# STM32N647xx register map
File version: 1.0
Registers are 32-bit, read-write, reset 0x0 unless marked. A register's access mark holds for its fields unless they carry their own. Offsets are from the block's base; [hi:lo] are bit positions.

## SYSCFG — System configuration controller
Base 0x46008000
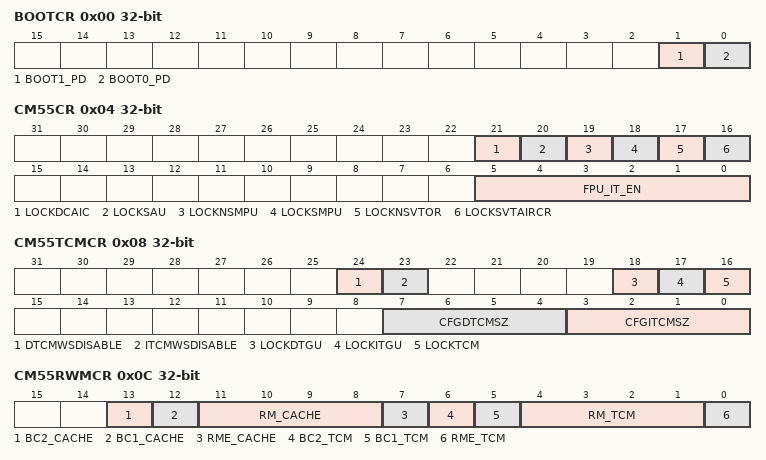
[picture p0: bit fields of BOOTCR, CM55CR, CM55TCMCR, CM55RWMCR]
0x00 BOOTCR — SYSCFG boot pin control register
  [1] BOOT1_PD — BOOT1 pin pull-down disable
  [0] BOOT0_PD — BOOT0 pin pull-down disable
0x04 CM55CR — SYSCFG Cortex-M55 control register
  [21] LOCKDCAIC
  [20] LOCKSAU — Prevent changes to secure SAU memory regions already programmed
  [19] LOCKNSMPU — Prevent changes to programmed non-secure MPU memory regions
  [18] LOCKSMPU — Prevent changes to programmed secure MPU memory regions
  [17] LOCKNSVTOR — Prevent changes to the non-secure vector table base address
  [16] LOCKSVTAIRCR
  [5:0] FPU_IT_EN — Enable FPU exception
0x08 CM55TCMCR — SYSCFG Cortex-M55 TCM control register
  [24] DTCMWSDISABLE — Disable wait-state applied by default on extended DTCM memory
  [23] ITCMWSDISABLE — Disable wait-state applied by default on extended ITCM memory
  [18] LOCKDTGU — Disable writes to registers associated with the DTCM interface security/gating
  [17] LOCKITGU — Disable writes to registers associated with the ITCM interface security/gating
  [16] LOCKTCM — Disable writes to registers associated with the TCM region
  [7:4] CFGDTCMSZ — Select DTCM memory size
  [3:0] CFGITCMSZ — Select ITCM memory size
0x0C CM55RWMCR — SYSCFG Cortex-M55 memory RW margin register
  [13] BC2_CACHE — Biasing level adjust input recommended for Vnom + 10%
  [12] BC1_CACHE — Biasing level adjust input recommended for Vnom
  [11:8] RM_CACHE — External read/write (RW) margin inputs for caches memories
  [7] RME_CACHE — RW margin enable input for caches memories
  [6] BC2_TCM — Biasing level adjust input recommended for Vnom + 10%
  [5] BC1_TCM — Biasing level adjust input recommended for Vnom
  [4:1] RM_TCM — External RW margin inputs for TCM memories
  [0] RME_TCM — RW margin enable input for TCM memories
0x10 INITSVTORCR — SYSCFG Cortex-M55 SVTOR control register
  [31:7] SVTOR_ADDR — Secure vector table base address
0x14 INITNSVTORCR — Cortex-M55 NSVTOR control register
  [31:7] NSVTOR_ADDR — Non-Secure vector table base address
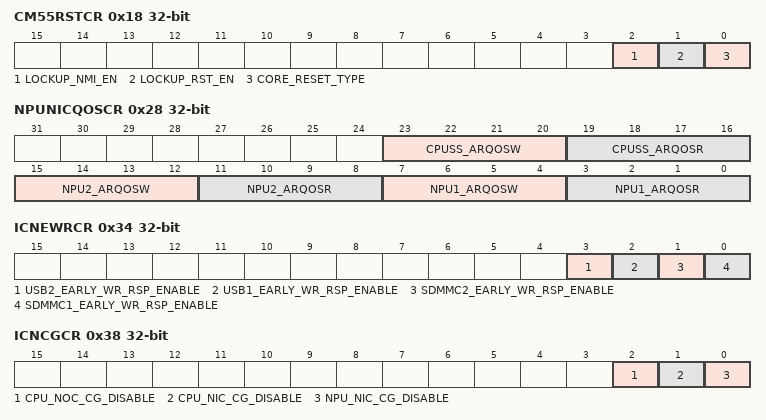
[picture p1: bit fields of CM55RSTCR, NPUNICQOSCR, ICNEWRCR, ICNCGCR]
0x18 CM55RSTCR — SYSCFG Cortex-M55 reset type control register
  [2] LOCKUP_NMI_EN — Select action to perform on a lockup state on the core
  [1] LOCKUP_RST_EN — Select action to perform on a lockup state on the core
  [0] CORE_RESET_TYPE — Select reset to apply on core upon SYSRESETREQ
0x1C CM55PAHBWPR — SYSCFG Cortex-M55 P-AHB write posting control register
  [0] PAHB_ERROR_ACK — Error capture in write posting buffer
0x20 VENCRAMCR — SYSCFG VENCRAM control register
  [0] VENCRAM_EN — VENCRAM allocation VENC if active, or to system (if VENC inactive)
0x24 POTTAMPRSTCR — SYSCFG potential tamper reset register
  [0] POTTAMPERSETMASK — mask PKA, SAES, CRYP1/2, and HASH reset, in case of potential tamper
0x28 NPUNICQOSCR — SYSCFG NPUNIC QoS control register
  [23:20] CPUSS_ARQOSW — NPUNIC write QoS information for master port from CPUSS
  [19:16] CPUSS_ARQOSR — NPUNIC read QoS information for master port from CPUSS
  [15:12] NPU2_ARQOSW — NPUNIC write QoS information for NPU2 master port
  [11:8] NPU2_ARQOSR — NPUNIC read QoS information for NPU2 master port
  [7:4] NPU1_ARQOSW — NPUNIC write QoS information for NPU1 master port
  [3:0] NPU1_ARQOSR — NPUNIC read QoS information for NPU1 master port
0x34 ICNEWRCR — SYSCFG AHB-AXI bridge early write response
  [3] USB2_EARLY_WR_RSP_ENABLE — USB2 early-write response
  [2] USB1_EARLY_WR_RSP_ENABLE — USB1 early-write response
  [1] SDMMC2_EARLY_WR_RSP_ENABLE — SDMMC2 early-write response
  [0] SDMMC1_EARLY_WR_RSP_ENABLE — SDMMC1 early-write response
0x38 ICNCGCR — SYSCFG ICN clock gating control register
  [2] CPU_NOC_CG_DISABLE — CPU_NOC clock gating disable
  [1] CPU_NIC_CG_DISABLE — CPU_NIC clock gating disable
  [0] NPU_NIC_CG_DISABLE — NPU_NIC clock gating disable
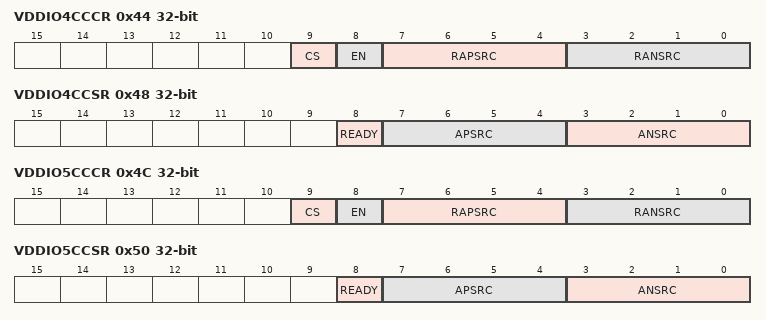
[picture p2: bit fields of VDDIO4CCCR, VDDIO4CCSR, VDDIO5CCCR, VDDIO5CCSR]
0x44 VDDIO4CCCR — SYSCFG VDDIO4 compensation cell control register
  [9] CS — Code selection for the compensation cell of I/Os supplied by VDDIO4
  [8] EN — Enables the compensation cell of I/Os supplied by VDDIO4
  [7:4] RAPSRC — I/O compensation code for PMOS transistors
  [3:0] RANSRC — I/O compensation code for NMOS transistors
0x48 VDDIO4CCSR — SYSCFG VDDIO4 compensation cell status register
  [8] READY — Provides the compensation cell status of I/Os supplied by VDDIO4
  [7:4] APSRC
  [3:0] ANSRC
0x4C VDDIO5CCCR — SYSCFG VDDIO5 compensation cell control register
  [9] CS — Code selection for the compensation cell of I/Os supplied by VDDIO5
  [8] EN — Enables the compensation cell of I/Os supplied by VDDIO5
  [7:4] RAPSRC — I/O compensation code for PMOS transistors
  [3:0] RANSRC — I/O compensation code for NMOS transistors
0x50 VDDIO5CCSR — SYSCFG VDDIO5 compensation cell status register
  [8] READY — Provides the compensation cell status of I/Os supplied by VDDIO5
  [7:4] APSRC
  [3:0] ANSRC
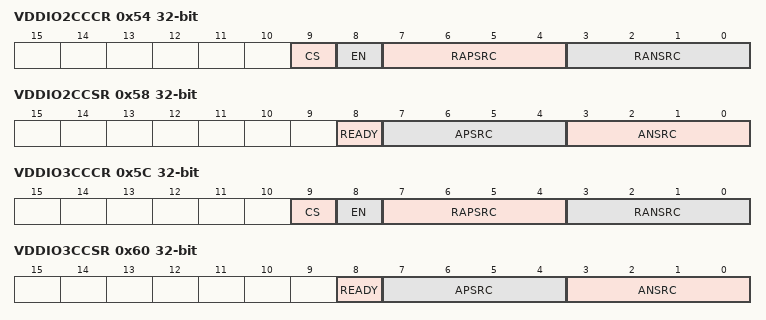
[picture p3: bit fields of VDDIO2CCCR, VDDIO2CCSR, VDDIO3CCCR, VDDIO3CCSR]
0x54 VDDIO2CCCR — SYSCFG VDDIO2 compensation cell control register
  [9] CS — Code selection for the compensation cell of I/Os supplied by VDDIO2
  [8] EN — Enables the compensation cell of I/Os supplied by VDDIO2
  [7:4] RAPSRC — I/O compensation code for PMOS transistors
  [3:0] RANSRC — I/O compensation code for NMOS transistors
0x58 VDDIO2CCSR — SYSCFG VDDIO2 compensation cell status register
  [8] READY — Provides the compensation cell status of I/Os supplied by VDDIO2
  [7:4] APSRC
  [3:0] ANSRC
0x5C VDDIO3CCCR — SYSCFG VDDIO3 compensation cell control register
  [9] CS — Code selection for the compensation cell of I/Os supplied by VDDIO3
  [8] EN — Enables the compensation cell of I/Os supplied by VDDIO3
  [7:4] RAPSRC — I/O compensation code for PMOS transistors
  [3:0] RANSRC — I/O compensation code for NMOS transistors
0x60 VDDIO3CCSR — SYSCFG VDDIO3 compensation cell status register
  [8] READY — Provides the compensation cell status of I/Os supplied by VDDIO3
  [7:4] APSRC
  [3:0] ANSRC
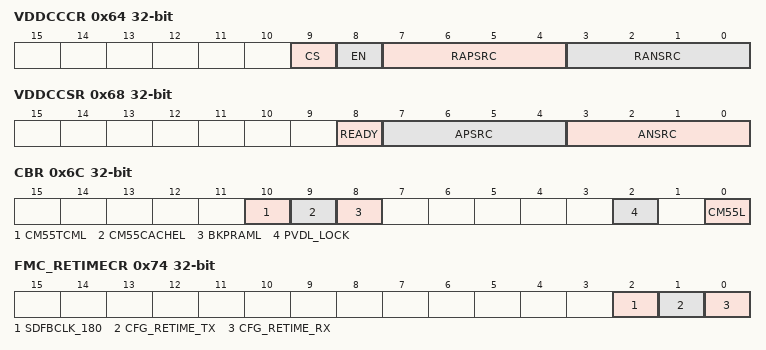
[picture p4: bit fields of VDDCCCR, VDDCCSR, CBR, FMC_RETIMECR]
0x64 VDDCCCR — SYSCFG VDD compensation cell control register
  [9] CS — Code selection for the compensation cell of I/Os supplied by VDD
  [8] EN — Enables the compensation cell of I/Os supplied by VDD
  [7:4] RAPSRC — I/O compensation code for PMOS transistors
  [3:0] RANSRC — I/O compensation code for NMOS transistors
0x68 VDDCCSR — SYSCFG VDD compensation cell status register
  [8] READY — Provides the compensation cell status of I/Os supplied by VDD
  [7:4] APSRC
  [3:0] ANSRC
0x6C CBR — SYSCFG control timer break register
  [10] CM55TCML — CM55 TCM double ECC error lock
  [9] CM55CACHEL — CM55 cache double ECC error lock
  [8] BKPRAML — Backup SRAM double ECC error lock
  [2] PVDL_LOCK — PVD lock enable
  [0] CM55L — CM55 lockup lock enable
0x70 SEC_AIDCR — SYSCFG DMA CID secure control register
  [2:0] DMACID_SEC
0x74 FMC_RETIMECR — SYSCFG FMC retiming logic control register
  [2] SDFBCLK_180 — Delay on feedback clock
  [1] CFG_RETIME_TX — Retiming on Tx path
  [0] CFG_RETIME_RX — Retiming on Rx path
0x78 NPU_ICNCR — SYSCFG NPU RAM interleaving control register
  [0] INTERLEAVING_ACTIVE — Control interleaving on NPU RAMs
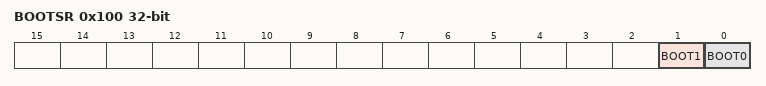
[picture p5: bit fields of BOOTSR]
0x100 BOOTSR — SYSCFG boot pin status register
  [1] BOOT1 — BOOT1 pin value
  [0] BOOT0 — BOOT0 pin value
0x104 AHBWP_ERROR_SR — SYSCFG AHB write posting address error register
  [31:0] PAHB_ERROR_ADDR — Reports address of the first error in P-AHB write-posting buffer
0x800 SECPRIV_AIDCR — SYSCFG DMA CID non-secure control register
  [2:0] DMACID_NONSEC
0xFF0 DEVICEID — SYSCFG Device ID
